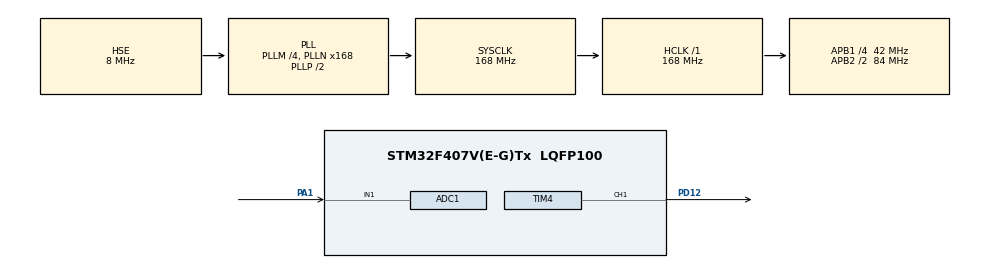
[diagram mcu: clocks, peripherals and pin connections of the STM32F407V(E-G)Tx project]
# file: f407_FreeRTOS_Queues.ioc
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ADC1.Channel-1\#ChannelRegularConversion=ADC_CHANNEL_1
ADC1.NbrOfConversionFlag=1
ADC1.Rank-1\#ChannelRegularConversion=1
ADC1.SamplingTime-1\#ChannelRegularConversion=ADC_SAMPLETIME_3CYCLES
ADC1.master=1
FREERTOS.Queues01=potKuyruk,16,uint16_t,0,Dynamic,NULL,NULL
FREERTOS.Tasks01=PotGorev,24,128,PotGorevFonksiyonu,Default,NULL,Dynamic,NULL,NULL;LEDParlakGorev,8,128,LEDParlakGorevFonksiyon,Default,NULL,Dynamic,NULL,NULL
FREERTOS.configUSE_NEWLIB_REENTRANT=1
Mcu.Family=STM32F4
Mcu.Name=STM32F407V(E-G)Tx
Mcu.Package=LQFP100
NVIC.PriorityGroup=NVIC_PRIORITYGROUP_4
NVIC.TIM1_UP_TIM10_IRQn=true\:15\:0\:false\:false\:true\:false\:false\:true\:true
NVIC.TimeBase=TIM1_UP_TIM10_IRQn
NVIC.TimeBaseIP=TIM1
PA1.Signal=ADCx_IN1
PA13.Mode=Serial_Wire
PA13.Signal=SYS_JTMS-SWDIO
PA14.Mode=Serial_Wire
PA14.Signal=SYS_JTCK-SWCLK
PD12.Signal=S_TIM4_CH1
PH0-OSC_IN.Mode=HSE-External-Oscillator
PH0-OSC_IN.Signal=RCC_OSC_IN
PH1-OSC_OUT.Mode=HSE-External-Oscillator
PH1-OSC_OUT.Signal=RCC_OSC_OUT
ProjectManager.HeapSize=0x200
ProjectManager.StackSize=0x400
ProjectManager.TargetToolchain=STM32CubeIDE
RCC.48MHZClocksFreq_Value=84000000
RCC.AHBFreq_Value=168000000
RCC.APB1CLKDivider=RCC_HCLK_DIV4
RCC.APB1Freq_Value=42000000
RCC.APB1TimFreq_Value=84000000
RCC.APB2CLKDivider=RCC_HCLK_DIV2
RCC.APB2Freq_Value=84000000
RCC.APB2TimFreq_Value=168000000
RCC.CortexFreq_Value=168000000
RCC.HCLKFreq_Value=168000000
RCC.HSE_VALUE=8000000
RCC.HSI_VALUE=16000000
RCC.LSE_VALUE=32768
RCC.PLLM=4
RCC.PLLN=168
RCC.PLLSourceVirtual=RCC_PLLSOURCE_HSE
RCC.SYSCLKFreq_VALUE=168000000
RCC.SYSCLKSource=RCC_SYSCLKSOURCE_PLLCLK
RCC.VCOOutputFreq_Value=336000000
SH.ADCx_IN1.0=ADC1_IN1,IN1
SH.S_TIM4_CH1.0=TIM4_CH1,PWM Generation1 CH1
TIM4.AutoReloadPreload=TIM_AUTORELOAD_PRELOAD_ENABLE
TIM4.Channel-PWM\ Generation1\ CH1=TIM_CHANNEL_1
VP_FREERTOS_VS_CMSIS_V2.Mode=CMSIS_V2
VP_SYS_VS_tim1.Mode=TIM1
VP_TIM4_VS_ClockSourceINT.Mode=Internal
board=custom

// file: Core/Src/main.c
/* USER CODE BEGIN Header */
/**
  ******************************************************************************
  * @file           : main.c
  * @brief          : Main program body
  ******************************************************************************
  * @attention
  *
  * Copyright (c) 2025 STMicroelectronics.
  * All rights reserved.
  *
  * This software is licensed under terms that can be found in the LICENSE file
  * in the root directory of this software component.
  * If no LICENSE file comes with this software, it is provided AS-IS.
  *
  ******************************************************************************
  */
/* USER CODE END Header */
#include "main.h"
#include "cmsis_os.h"

ADC_HandleTypeDef hadc1;

TIM_HandleTypeDef htim4;

/* Definitions for PotGorev */
osThreadId_t PotGorevHandle;
const osThreadAttr_t PotGorev_attributes = {
  .name = "PotGorev",
  .stack_size = 128 * 4,
  .priority = (osPriority_t) osPriorityNormal,
};
/* Definitions for LEDParlakGorev */
osThreadId_t LEDParlakGorevHandle;
const osThreadAttr_t LEDParlakGorev_attributes = {
  .name = "LEDParlakGorev",
  .stack_size = 128 * 4,
  .priority = (osPriority_t) osPriorityLow,
};
/* Definitions for potKuyruk */
osMessageQueueId_t potKuyrukHandle;
const osMessageQueueAttr_t potKuyruk_attributes = {
  .name = "potKuyruk"
};

void SystemClock_Config(void);
static void MX_GPIO_Init(void);
static void MX_ADC1_Init(void);
static void MX_TIM4_Init(void);
void PotGorevFonksiyonu(void *argument);
void LEDParlakGorevFonksiyon(void *argument);

int main(void)
{

  /* MCU Configuration--------------------------------------------------------*/

  /* Reset of all peripherals, Initializes the Flash interface and the Systick. */
  HAL_Init();

  /* Configure the system clock */
  SystemClock_Config();

  /* Initialize all configured peripherals */
  MX_GPIO_Init();
  MX_ADC1_Init();
  MX_TIM4_Init();
  /* USER CODE BEGIN 2 */
  HAL_TIM_PWM_Start(&htim4, TIM_CHANNEL_1);

  /* USER CODE END 2 */

  /* Init scheduler */
  osKernelInitialize();

  /* Create the queue(s) */
  /* creation of potKuyruk */
  potKuyrukHandle = osMessageQueueNew (16, sizeof(uint16_t), &potKuyruk_attributes);

  /* Create the thread(s) */
  /* creation of PotGorev */
  PotGorevHandle = osThreadNew(PotGorevFonksiyonu, NULL, &PotGorev_attributes);

  /* creation of LEDParlakGorev */
  LEDParlakGorevHandle = osThreadNew(LEDParlakGorevFonksiyon, NULL, &LEDParlakGorev_attributes);

  /* Start scheduler */
  osKernelStart();

  /* We should never get here as control is now taken by the scheduler */

  /* Infinite loop */
  while (1)
  {

  }
}

void SystemClock_Config(void)
{
  RCC_OscInitTypeDef RCC_OscInitStruct = {0};
  RCC_ClkInitTypeDef RCC_ClkInitStruct = {0};

  /** Configure the main internal regulator output voltage
  */
  __HAL_RCC_PWR_CLK_ENABLE();
  __HAL_PWR_VOLTAGESCALING_CONFIG(PWR_REGULATOR_VOLTAGE_SCALE1);

  /** Initializes the RCC Oscillators according to the specified parameters
  * in the RCC_OscInitTypeDef structure.
  */
  RCC_OscInitStruct.OscillatorType = RCC_OSCILLATORTYPE_HSE;
  RCC_OscInitStruct.HSEState = RCC_HSE_ON;
  RCC_OscInitStruct.PLL.PLLState = RCC_PLL_ON;
  RCC_OscInitStruct.PLL.PLLSource = RCC_PLLSOURCE_HSE;
  RCC_OscInitStruct.PLL.PLLM = 4;
  RCC_OscInitStruct.PLL.PLLN = 168;
  RCC_OscInitStruct.PLL.PLLP = RCC_PLLP_DIV2;
  RCC_OscInitStruct.PLL.PLLQ = 4;
  if (HAL_RCC_OscConfig(&RCC_OscInitStruct) != HAL_OK)
  {
    Error_Handler();
  }

  /** Initializes the CPU, AHB and APB buses clocks
  */
  RCC_ClkInitStruct.ClockType = RCC_CLOCKTYPE_HCLK|RCC_CLOCKTYPE_SYSCLK
                              |RCC_CLOCKTYPE_PCLK1|RCC_CLOCKTYPE_PCLK2;
  RCC_ClkInitStruct.SYSCLKSource = RCC_SYSCLKSOURCE_PLLCLK;
  RCC_ClkInitStruct.AHBCLKDivider = RCC_SYSCLK_DIV1;
  RCC_ClkInitStruct.APB1CLKDivider = RCC_HCLK_DIV4;
  RCC_ClkInitStruct.APB2CLKDivider = RCC_HCLK_DIV2;

  if (HAL_RCC_ClockConfig(&RCC_ClkInitStruct, FLASH_LATENCY_5) != HAL_OK)
  {
    Error_Handler();
  }
}

static void MX_ADC1_Init(void)
{

  ADC_ChannelConfTypeDef sConfig = {0};

  /** Configure the global features of the ADC (Clock, Resolution, Data Alignment and number of conversion)
  */
  hadc1.Instance = ADC1;
  hadc1.Init.ClockPrescaler = ADC_CLOCK_SYNC_PCLK_DIV4;
  hadc1.Init.Resolution = ADC_RESOLUTION_12B;
  hadc1.Init.ScanConvMode = DISABLE;
  hadc1.Init.ContinuousConvMode = DISABLE;
  hadc1.Init.DiscontinuousConvMode = DISABLE;
  hadc1.Init.ExternalTrigConvEdge = ADC_EXTERNALTRIGCONVEDGE_NONE;
  hadc1.Init.ExternalTrigConv = ADC_SOFTWARE_START;
  hadc1.Init.DataAlign = ADC_DATAALIGN_RIGHT;
  hadc1.Init.NbrOfConversion = 1;
  hadc1.Init.DMAContinuousRequests = DISABLE;
  hadc1.Init.EOCSelection = ADC_EOC_SINGLE_CONV;
  if (HAL_ADC_Init(&hadc1) != HAL_OK)
  {
    Error_Handler();
  }

  /** Configure for the selected ADC regular channel its corresponding rank in the sequencer and its sample time.
  */
  sConfig.Channel = ADC_CHANNEL_1;
  sConfig.Rank = 1;
  sConfig.SamplingTime = ADC_SAMPLETIME_3CYCLES;
  if (HAL_ADC_ConfigChannel(&hadc1, &sConfig) != HAL_OK)
  {
    Error_Handler();
  }

}

static void MX_TIM4_Init(void)
{

  TIM_ClockConfigTypeDef sClockSourceConfig = {0};
  TIM_MasterConfigTypeDef sMasterConfig = {0};
  TIM_OC_InitTypeDef sConfigOC = {0};

  htim4.Instance = TIM4;
  htim4.Init.Prescaler = 0;
  htim4.Init.CounterMode = TIM_COUNTERMODE_UP;
  htim4.Init.Period = 65535;
  htim4.Init.ClockDivision = TIM_CLOCKDIVISION_DIV1;
  htim4.Init.AutoReloadPreload = TIM_AUTORELOAD_PRELOAD_ENABLE;
  if (HAL_TIM_Base_Init(&htim4) != HAL_OK)
  {
    Error_Handler();
  }
  sClockSourceConfig.ClockSource = TIM_CLOCKSOURCE_INTERNAL;
  if (HAL_TIM_ConfigClockSource(&htim4, &sClockSourceConfig) != HAL_OK)
  {
    Error_Handler();
  }
  if (HAL_TIM_PWM_Init(&htim4) != HAL_OK)
  {
    Error_Handler();
  }
  sMasterConfig.MasterOutputTrigger = TIM_TRGO_RESET;
  sMasterConfig.MasterSlaveMode = TIM_MASTERSLAVEMODE_DISABLE;
  if (HAL_TIMEx_MasterConfigSynchronization(&htim4, &sMasterConfig) != HAL_OK)
  {
    Error_Handler();
  }
  sConfigOC.OCMode = TIM_OCMODE_PWM1;
  sConfigOC.Pulse = 0;
  sConfigOC.OCPolarity = TIM_OCPOLARITY_HIGH;
  sConfigOC.OCFastMode = TIM_OCFAST_DISABLE;
  if (HAL_TIM_PWM_ConfigChannel(&htim4, &sConfigOC, TIM_CHANNEL_1) != HAL_OK)
  {
    Error_Handler();
  }
  HAL_TIM_MspPostInit(&htim4);

}

static void MX_GPIO_Init(void)
{

  /* GPIO Ports Clock Enable */
  __HAL_RCC_GPIOH_CLK_ENABLE();
  __HAL_RCC_GPIOA_CLK_ENABLE();
  __HAL_RCC_GPIOD_CLK_ENABLE();

}

void PotGorevFonksiyonu(void *argument)
{
  /* USER CODE BEGIN 5 */
  /* Infinite loop */
	uint16_t adcDeger=0;

	osStatus sistemDurum;

  for(;;)
  {
	  HAL_ADC_Start(&hadc1);
	  HAL_ADC_PollForConversion(&hadc1, 1);
	  adcDeger = HAL_ADC_GetValue(&hadc1);
	  // oMessageQueuePut(Kuyruk ID, Veri Adresi, Öncelik (0 en düşük), Bekleme Süresi (Timeout))
	  osMessageQueuePut(potKuyrukHandle, &adcDeger, 0, 1);

	  if(sistemDurum!=osOK)
	  {
		  //kuyruk dolu
	  }

    vTaskDelay(1);
  }
  /* USER CODE END 5 */
}

void LEDParlakGorevFonksiyon(void *argument)
{
  /* USER CODE BEGIN LEDParlakGorevFonksiyon */
  /* Infinite loop */
	uint16_t potDeger;
	osStatus sistemDurumu;
  for(;;)
  {

	 // 1. Kuyruktan Veriyi Oku
	 // osMessageQueueGet(Kuyruk ID, Veri Adresi, Öncelik, Bekleme Süresi)
	 sistemDurumu = osMessageQueueGet(potKuyrukHandle, &potDeger, NULL, osWaitForever);
	 // osWaitForever: Veri gelene kadar bu görevi askıya al.
	 if (sistemDurumu == osOK)
	 {
	    TIM4->CCR1=(potDeger<<4);
	 }
	 else
	 {
	 // Nadiren olur, ancak hata durumlarını (örn. kuyruğun silinmesi) ele alın.
	 }

	 // Bu görev, osWaitForever kullandığı için ek bir osDelay'e ihtiyaç duymaz.
	 // Yalnızca veri geldiğinde uyanır.

    osDelay(1);
  }
  /* USER CODE END LEDParlakGorevFonksiyon */
}

void HAL_TIM_PeriodElapsedCallback(TIM_HandleTypeDef *htim)
{
  if (htim->Instance == TIM1)
  {
    HAL_IncTick();
  }
}

void Error_Handler(void)
{
  __disable_irq();
  while (1)
  {
  }
}
